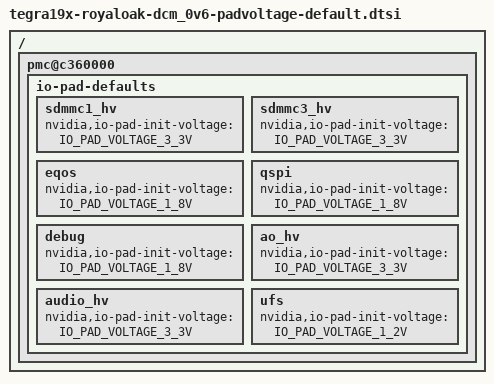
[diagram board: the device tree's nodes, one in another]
/*This dtsi file was generated by dcm_0v6.xlsm Revision: 1.06 */
/*
 * Copyright (c) 2017, NVIDIA CORPORATION.  All rights reserved.
 *
 * This program is free software; you can redistribute it and/or modify
 * it under the terms of the GNU General Public License as published by
 * the Free Software Foundation; either version 2 of the License, or
 * (at your option) any later version.
 *
 * This program is distributed in the hope that it will be useful, but WITHOUT
 * ANY WARRANTY; without even the implied warranty of MERCHANTABILITY or
 * FITNESS FOR A PARTICULAR PURPOSE.  See the GNU General Public License for
 * more details.
 */

/ {
	pmc@c360000 {
		io-pad-defaults {
			sdmmc1_hv {
				nvidia,io-pad-init-voltage = <IO_PAD_VOLTAGE_3_3V>;
			};

			sdmmc3_hv {
				nvidia,io-pad-init-voltage = <IO_PAD_VOLTAGE_3_3V>;
			};

			eqos {
				nvidia,io-pad-init-voltage = <IO_PAD_VOLTAGE_1_8V>;
			};

			qspi {
				nvidia,io-pad-init-voltage = <IO_PAD_VOLTAGE_1_8V>;
			};

			debug {
				nvidia,io-pad-init-voltage = <IO_PAD_VOLTAGE_1_8V>;
			};

			ao_hv {
				nvidia,io-pad-init-voltage = <IO_PAD_VOLTAGE_3_3V>;
			};

			audio_hv {
				nvidia,io-pad-init-voltage = <IO_PAD_VOLTAGE_3_3V>;
			};

			ufs {
				nvidia,io-pad-init-voltage = <IO_PAD_VOLTAGE_1_2V>;
			};

		};
	};
};
